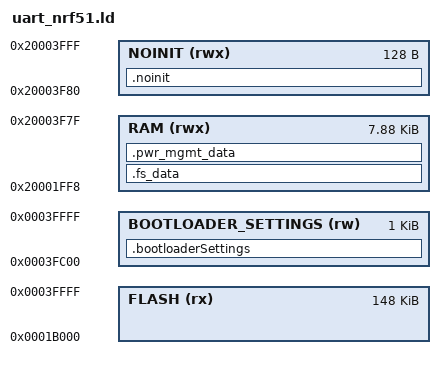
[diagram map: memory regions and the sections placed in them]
/* Linker script to configure memory regions. */

SEARCH_DIR(.)
GROUP(-lgcc -lc -lnosys)

MEMORY
{
  FLASH (rx) : ORIGIN = 0x0001b000, LENGTH = 0x25000
  RAM (rwx) :  ORIGIN = 0x20001ff8, LENGTH = 0x1F88
  NOINIT (rwx) :  ORIGIN = 0x20003F80, LENGTH = 0x80
  BOOTLOADER_SETTINGS (rw) : ORIGIN = 0x0003FC00, LENGTH = 0x0400
}

SECTIONS
{
  /* Ensures the bootloader settings are placed at the last flash page. */
  .bootloaderSettings(NOLOAD) :
  {

  } > BOOTLOADER_SETTINGS

  /* No init RAM section in bootloader. Used for bond information exchange. */
  
  .noinit(NOLOAD) :
  {

  } > NOINIT

  .fs_data :
  {
    PROVIDE(__start_fs_data = .);
    KEEP(*(.fs_data))
    PROVIDE(__stop_fs_data = .);
  } > RAM
  .pwr_mgmt_data :
  {
    PROVIDE(__start_pwr_mgmt_data = .);
    KEEP(*(.pwr_mgmt_data))
    PROVIDE(__stop_pwr_mgmt_data = .);
  } > RAM
} INSERT AFTER .data;

INCLUDE "nrf5x_common.ld"
